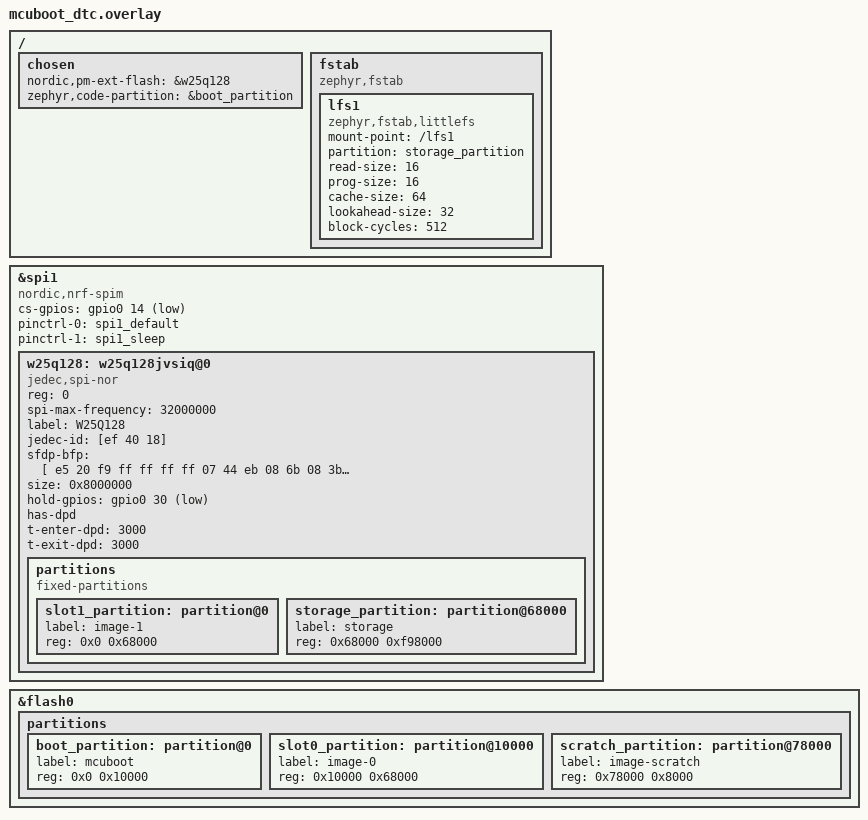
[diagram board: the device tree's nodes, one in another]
// To get started, press Ctrl+Space to bring up the completion menu and view the available nodes.

// You can also use the buttons in the sidebar to perform actions on nodes.
// Actions currently available include:

// * Enabling / disabling the node
// * Adding the bus to a bus
// * Removing the node
// * Connecting ADC channels

// For more help, browse the DeviceTree documentation at https://docs.zephyrproject.org/latest/guides/dts/index.html
// You can also visit the nRF DeviceTree extension documentation at https://nrfconnect.github.io/vscode-nrf-connect/devicetree/nrfdevicetree.html
/{
    chosen {
        nordic,pm-ext-flash   = &w25q128;
		zephyr,code-partition = &boot_partition;
    };

	fstab {
		compatible = "zephyr,fstab";
		lfs1: lfs1 {
			compatible = "zephyr,fstab,littlefs";
			mount-point = "/lfs1";
			partition = <&storage_partition>;
			read-size = <16>;
			prog-size = <16>;
			cache-size = <64>;
			lookahead-size = <32>;
			block-cycles = <512>;
		};
	};
};


&spi1 {
	compatible = "nordic,nrf-spim";
	status = "okay";
	cs-gpios = <&gpio0 14 GPIO_ACTIVE_LOW>;
	pinctrl-0 = <&spi1_default>;
	pinctrl-1 = <&spi1_sleep>;
	pinctrl-names = "default", "sleep";

    w25q128:w25q128jvsiq@0 {
        compatible = "jedec,spi-nor";
        reg = <0>;
        spi-max-frequency = <32000000>;
        label = "W25Q128";
        jedec-id = [ef 40 18];
        sfdp-bfp = [ 
            e5 20 f9 ff  ff ff ff 07  44 eb 08 6b  08 3b 42 bb
            fe ff ff ff  ff ff 00 00  ff ff 40 eb  0c 20 0f 52
            10 d8 00 00  36 02 a6 00  82 ea 14 c9  e9 63 76 33
            7a 75 7a 75  f7 a2 d5 5c  19 f7 4d ff  e9 30 f8 80
        ];
        size = <0x8000000>;
        hold-gpios = <&gpio0 30 GPIO_ACTIVE_LOW>;
        has-dpd;
        t-enter-dpd = <3000>;
        t-exit-dpd = <3000>;
    };
};
//simply overlaying new &flash0 will not redefine partition
//one way to mitigate it is to use the /delete-node/ device tree directive here
//which may not be a standard practice for device tree
//however, in Zephyr <board>.overlay files are appended to <board>.dts using c preprocessor
//which is not a standanard practice for device tree as well 
//check Zephyr.dts from the build folder to see the final result
/delete-node/ &boot_partition;
/delete-node/ &slot0_partition;
/delete-node/ &slot1_partition;
/delete-node/ &scratch_partition;
/delete-node/ &storage_partition;
&flash0 {
    partitions {
		boot_partition: partition@0 {
			label = "mcuboot";
			reg = <0x0 0x10000>;
		};

		slot0_partition: partition@10000 {
			label = "image-0";
			reg = <0x10000 0x68000>;
		};
		scratch_partition: partition@78000 {
			label = "image-scratch";
			reg = <0x78000 0x8000>;
		};
    };
};

&w25q128 {
    partitions {
        compatible = "fixed-partitions"; 
        #address-cells = <1>;
        #size-cells = <1>;
		slot1_partition: partition@0 {
			label = "image-1";
			reg = <0x0 0x68000>;
		};
		storage_partition: partition@68000 {
			label = "storage";
			reg = <0x68000 0xf98000>;
		};
    };
};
